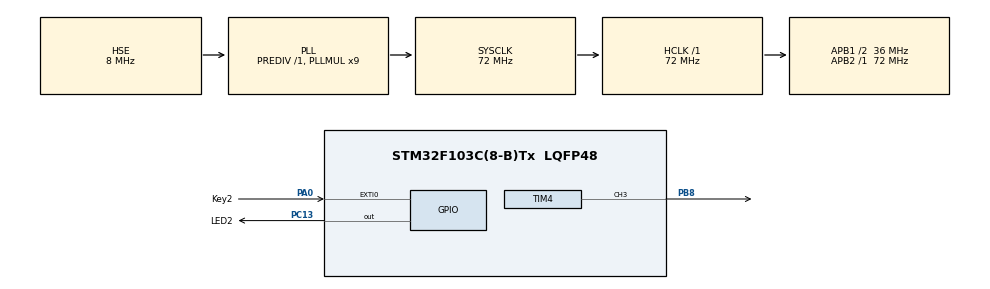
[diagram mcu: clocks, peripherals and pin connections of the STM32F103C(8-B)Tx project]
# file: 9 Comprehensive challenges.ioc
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Mcu.Family=STM32F1
Mcu.Name=STM32F103C(8-B)Tx
Mcu.Package=LQFP48
NVIC.EXTI0_IRQn=true\:0\:0\:false\:false\:true\:true\:true\:true
NVIC.PriorityGroup=NVIC_PRIORITYGROUP_4
NVIC.TIM4_IRQn=true\:0\:0\:false\:false\:true\:true\:true\:true
PA0-WKUP.GPIO_Label=Key2
PA0-WKUP.GPIO_ModeDefaultEXTI=GPIO_MODE_IT_FALLING
PA0-WKUP.GPIO_PuPd=GPIO_PULLUP
PA0-WKUP.Signal=GPXTI0
PA13.Mode=Serial_Wire
PA13.Signal=SYS_JTMS-SWDIO
PA14.Mode=Serial_Wire
PA14.Signal=SYS_JTCK-SWCLK
PB8.Signal=S_TIM4_CH3
PC13-TAMPER-RTC.GPIO_Label=LED2
PC13-TAMPER-RTC.PinState=GPIO_PIN_RESET
PC13-TAMPER-RTC.Signal=GPIO_Output
PD0-OSC_IN.Mode=HSE-External-Oscillator
PD0-OSC_IN.Signal=RCC_OSC_IN
PD1-OSC_OUT.Mode=HSE-External-Oscillator
PD1-OSC_OUT.Signal=RCC_OSC_OUT
ProjectManager.HeapSize=0x200
ProjectManager.StackSize=0x400
ProjectManager.TargetToolchain=MDK-ARM V5.32
RCC.AHBFreq_Value=72000000
RCC.APB1CLKDivider=RCC_HCLK_DIV2
RCC.APB1Freq_Value=36000000
RCC.APB1TimFreq_Value=72000000
RCC.APB2Freq_Value=72000000
RCC.APB2TimFreq_Value=72000000
RCC.HCLKFreq_Value=72000000
RCC.PLLMUL=RCC_PLL_MUL9
RCC.PLLSourceVirtual=RCC_PLLSOURCE_HSE
RCC.SYSCLKFreq_VALUE=72000000
RCC.SYSCLKSource=RCC_SYSCLKSOURCE_PLLCLK
RCC.USBFreq_Value=72000000
SH.S_TIM4_CH3.0=TIM4_CH3,PWM Generation3 CH3
TIM4.AutoReloadPreload=TIM_AUTORELOAD_PRELOAD_ENABLE
TIM4.Channel-PWM\ Generation3\ CH3=TIM_CHANNEL_3
TIM4.OCPolarity_3=TIM_OCPOLARITY_LOW
TIM4.Period=499
TIM4.Prescaler=71
VP_TIM4_VS_ClockSourceINT.Mode=Internal
board=custom

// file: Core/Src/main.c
/* USER CODE BEGIN Header */
/**
  ******************************************************************************
  * @file           : main.c
  * @brief          : Main program body
  ******************************************************************************
  * @attention
  *
  * Copyright (c) 2024 STMicroelectronics.
  * All rights reserved.
  *
  * This software is licensed under terms that can be found in the LICENSE file
  * in the root directory of this software component.
  * If no LICENSE file comes with this software, it is provided AS-IS.
  *
  ******************************************************************************
  */

	//用了pwm，需要将 PB8 与 PC13 短接
	//单击：在1s内只按一次按钮。每单击一次按钮，调节LED亮度。
	//双击：在1s内按两次按钮，进入呼吸灯。如需关闭，单击一次按钮，等待一个呼吸灯周期，关闭
	//长按：长按按钮在2s以上，进入闪烁灯。如需关闭，单击一次按钮，关闭

/* USER CODE END Header */
#include "main.h"
#include "tim.h"
#include "gpio.h"

/* USER CODE BEGIN PTD */
#define key2_flag 1
#define key2 HAL_GPIO_ReadPin(Key2_GPIO_Port, Key2_Pin)
uint8_t key_flag;
int key_mode = -1;//0单击 1双击 2长按
int begin_flag = 0;
int times = 0;//计算按键次数
int times_ok = 0;//存放次数
int t = 0;
int counts = 0;
int temp;//计时按键按下的时间
int sign = 0;
/* USER CODE END PTD */

void SystemClock_Config(void);

/* USER CODE BEGIN 0 */
int lasttime = 0;
void HAL_GPIO_EXTI_Callback(uint16_t GPIO_Pin)
{

	if(HAL_GetTick() - lasttime > 200)
	{
		if(times == 0)
		counts = (counts + 1)%4;

		if(times > 1)
				times = 0;

		if(times == 1)
		{
			__HAL_TIM_SET_COMPARE(&htim4, TIM_CHANNEL_3,0);
			key_mode = 0;
			counts = 0;
			times = 0;
		}

		if(key_mode == 2)
		{
			__HAL_TIM_SET_COMPARE(&htim4, TIM_CHANNEL_3,0);
			temp = 0;
			counts  = 0;
			key_mode = 0;
		}
		if(HAL_GetTick() - lasttime < 1000)
		{
			//times = (times + 1)%2;
			times++;
		}

	}
	lasttime = HAL_GetTick();

}

int Fact(int num)
{
	int sum = 1;
	for(int i = 0; i < num; i++)
	{
		sum = sum*10;
	}
	return sum;
}

void key2_scan(void)
{

/*	if(HAL_GPIO_ReadPin(Key2_GPIO_Port, Key2_Pin)==GPIO_PIN_RESET)
	{
		HAL_Delay(5);
		if(begin_flag == 0)
		{
			HAL_TIM_Base_Start_IT(&htim4);
			__HAL_TIM_SetCounter(&htim4,0);
		  begin_flag = 1;
		}
	  if(begin_flag == 1)
		{
				if(HAL_GPIO_ReadPin(Key2_GPIO_Port, Key2_Pin) == GPIO_PIN_RESET)
					times++;
		}
	}*/

}//不知道为什么不能正常调用该函数，可能时钟没调好？？？？

int Key2_Scan(void)
{
//	static uint8_t flag = 1;//是否被按下

//	if(flag == 1)
//	{
		HAL_Delay(100);
		if(key2 == 0)
		{
//			flag = 0;
			temp = 0;
			while(key2 == 0 && temp < 100)
			{
				temp++;
				HAL_Delay(50);
			}
			key_flag = key2_flag;

		}
		return temp;
//	}
	/*else
	{
		flag = 1;
		key_flag = 0;
	}
	return 0;
	*/
}

void Key2_Mode(void)
{
	int key_t;
	key_t = Key2_Scan();

	if(key_t >= 0 && key_t<= 20)
	{

		//	key2_scan();
			if(times == 0)
			{
				key_mode = 0;
			}//单击

			if(times == 1)
			{
				key_mode = 1;
			}//双击

	}
	else if(key_t > 38)
	{
		key_mode = 2;
	}//长按
}

void HAL_TIM_PeriodElapsedCallback(TIM_HandleTypeDef *htim)
{
	if(htim->Instance == TIM4)
    {
       begin_flag=0;
			 times_ok=times;
			 times=0;

    }
   HAL_TIM_Base_Stop_IT(&htim4);

}

/* USER CODE END 0 */

int main(void)
{
  /* USER CODE BEGIN 1 */
int nums = 0;
  /* USER CODE END 1 */

  /* MCU Configuration--------------------------------------------------------*/

  /* Reset of all peripherals, Initializes the Flash interface and the Systick. */
  HAL_Init();

  /* Configure the system clock */
  SystemClock_Config();

  /* Initialize all configured peripherals */
  MX_GPIO_Init();
  MX_TIM4_Init();
  /* USER CODE BEGIN 2 */
	__HAL_TIM_CLEAR_FLAG(&htim4, TIM_IT_UPDATE);
   HAL_TIM_Base_Stop_IT(&htim4);
	 HAL_TIM_PWM_Start(&htim4,TIM_CHANNEL_3);
  /* USER CODE END 2 */

  /* Infinite loop */
  /* USER CODE BEGIN WHILE */
  while (1)
  {
		Key2_Mode();
		switch(key_mode)
		{
			case 0:
				__HAL_TIM_SET_COMPARE(&htim4,TIM_CHANNEL_3,Fact(counts)-1);//0 9 99 999
			HAL_Delay(200);
			break;

			case 1:
				while(nums< 800)
				{
					nums++;
					__HAL_TIM_SetCompare(&htim4,TIM_CHANNEL_3,nums);
					HAL_Delay(2);

				}
				while(nums)
				{
					nums--;
					__HAL_TIM_SetCompare(&htim4,TIM_CHANNEL_3,nums);
					HAL_Delay(2);

				}
				HAL_Delay(200);
				break;

			case 2:

				__HAL_TIM_SET_COMPARE(&htim4, TIM_CHANNEL_3,125);
				HAL_Delay(temp*25);
				__HAL_TIM_SET_COMPARE(&htim4, TIM_CHANNEL_3,0);
				HAL_Delay(temp*25);
			break;

			default:
				break;

		}
	}
    /* USER CODE END WHILE */

}

void SystemClock_Config(void)
{
  RCC_OscInitTypeDef RCC_OscInitStruct = {0};
  RCC_ClkInitTypeDef RCC_ClkInitStruct = {0};

  /** Initializes the RCC Oscillators according to the specified parameters
  * in the RCC_OscInitTypeDef structure.
  */
  RCC_OscInitStruct.OscillatorType = RCC_OSCILLATORTYPE_HSE;
  RCC_OscInitStruct.HSEState = RCC_HSE_ON;
  RCC_OscInitStruct.HSEPredivValue = RCC_HSE_PREDIV_DIV1;
  RCC_OscInitStruct.HSIState = RCC_HSI_ON;
  RCC_OscInitStruct.PLL.PLLState = RCC_PLL_ON;
  RCC_OscInitStruct.PLL.PLLSource = RCC_PLLSOURCE_HSE;
  RCC_OscInitStruct.PLL.PLLMUL = RCC_PLL_MUL9;
  if (HAL_RCC_OscConfig(&RCC_OscInitStruct) != HAL_OK)
  {
    Error_Handler();
  }

  /** Initializes the CPU, AHB and APB buses clocks
  */
  RCC_ClkInitStruct.ClockType = RCC_CLOCKTYPE_HCLK|RCC_CLOCKTYPE_SYSCLK
                              |RCC_CLOCKTYPE_PCLK1|RCC_CLOCKTYPE_PCLK2;
  RCC_ClkInitStruct.SYSCLKSource = RCC_SYSCLKSOURCE_PLLCLK;
  RCC_ClkInitStruct.AHBCLKDivider = RCC_SYSCLK_DIV1;
  RCC_ClkInitStruct.APB1CLKDivider = RCC_HCLK_DIV2;
  RCC_ClkInitStruct.APB2CLKDivider = RCC_HCLK_DIV1;

  if (HAL_RCC_ClockConfig(&RCC_ClkInitStruct, FLASH_LATENCY_2) != HAL_OK)
  {
    Error_Handler();
  }
}

void Error_Handler(void)
{
  __disable_irq();
  while (1)
  {
  }
}
